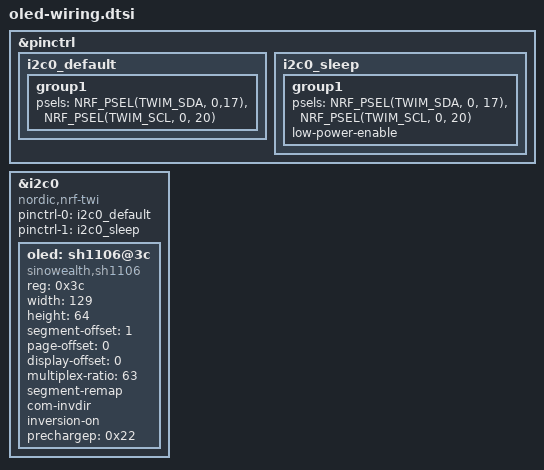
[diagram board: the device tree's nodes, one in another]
/* Copyright (c) 2021 Darryl deHaan
 * SPDX-License-Identifier: MIT
 * Wiring/dimensions copied from Obrey's uploaded Corne dongle overlay.
 * Source archive commit 717d5d7abb7145f01c93384b03ee5a699d72054e.
 * Retains SDA=P0.17, SCL=P0.20, address=0x3c and original width=129.
 * Uses the stock ZMK screen, not the old v0.3 dongle-display extension.
 */
&pinctrl {
    i2c0_default: i2c0_default {
        group1 {
            psels = <NRF_PSEL(TWIM_SDA, 0,17)>,
                <NRF_PSEL(TWIM_SCL, 0, 20)>;
        };
    };

    i2c0_sleep: i2c0_sleep {
        group1 {
            psels = <NRF_PSEL(TWIM_SDA, 0, 17)>,
                <NRF_PSEL(TWIM_SCL, 0, 20)>;
            low-power-enable;
        };
    };	
}; 

&i2c0 {
	status = "okay";
	compatible = "nordic,nrf-twi";
    pinctrl-0 = <&i2c0_default>;
    pinctrl-1 = <&i2c0_sleep>;
    pinctrl-names = "default", "sleep";
	oled: sh1106@3c {
        compatible = "sinowealth,sh1106";
        reg = <0x3c>;
        width = <129>;
        height = <64>;
        segment-offset = <1>;
        page-offset = <0>;
        display-offset = <0>;
        multiplex-ratio = <63>;
        segment-remap;
        com-invdir;
        inversion-on;
        prechargep = <0x22>;
	};
};
